# NPCX498S register map
File version: 1.0
Registers are 8-bit, read-write, reset 0x0 unless marked. A register's access mark holds for its fields unless they carry their own. Offsets are from the block's base; [hi:lo] are bit positions; {n}, {i} and the like mark numbered series.

## SYS_CONFIG
Base 0x400C3000
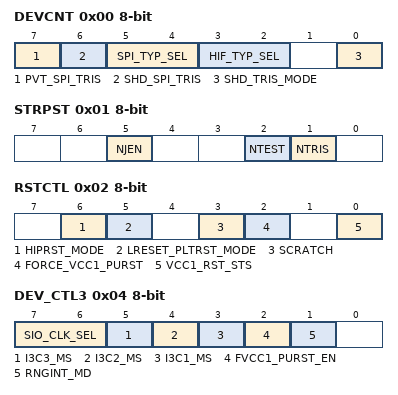
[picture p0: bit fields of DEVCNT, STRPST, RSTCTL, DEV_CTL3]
0x00 DEVCNT — Device Control Register (DEVCNT)
  [7] PVT_SPI_TRIS — Private Flash SPI Interface TRI-STATE
  [6] SHD_SPI_TRIS — Shared Flash SPI Interface TRI-STATE
  [5:4] SPI_TYP_SEL — SPI Interface Type Select
  [3:2] HIF_TYP_SEL — Host Interface Type Select
  [0] SHD_TRIS_MODE — Shared Flash SPI TRI-STATE Mode
0x01 STRPST — Straps Status Register (STRPST)
  [5] NJEN — JTAG Strap
  [2] NTEST — XOR-Tree Test Mode
  [1] NTRIS — TRI-STATE Test Mode
0x02 RSTCTL — Reset Control and Status Register (RSTCTL)
  [6] HIPRST_MODE — Host Interface Modules Reset Mode Select
  [5] LRESET_PLTRST_MODE — LRESET or PLTRST Mode Select
  [3] SCRATCH
  [2] FORCE_VCC1_PURST — Force VCC1 Power-Up Reset
  [0] VCC1_RST_STS — VCC1_RST Status
0x04 DEV_CTL3 — Device Control 3 Register (DEV_CTL3)
  [7:6] SIO_CLK_SEL — SIO Modules Clock Select
  [5] I3C3_MS — I3CI3 Module Controller/Target Select
  [4] I3C2_MS — I3CI2 Module Controller/Target Select
  [3] I3C1_MS — I3CI1 Module Controller/Target Select
  [2] FVCC1_PURST_EN — Force VCC1 Power-Up Reset Enable
  [1] RNGINT_MD — RNG Modules Interrupt Mode
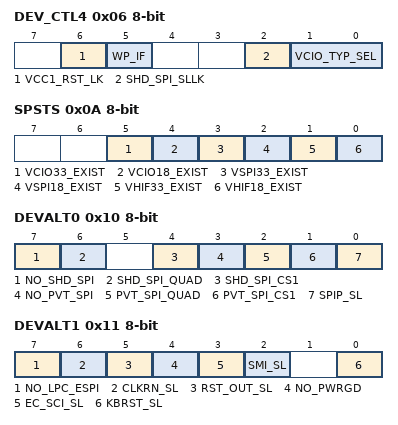
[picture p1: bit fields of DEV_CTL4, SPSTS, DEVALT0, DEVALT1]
0x06 DEV_CTL4 — Device Control 4 Register (DEV_CTL4)
  [6] VCC1_RST_LK — NO_VCC1_RST Bit Lock
  [5] WP_IF — Write-Protect Internal Flash
  [2] SHD_SPI_SLLK — Shared Flash SPI Interface-Select Lock
  [1:0] VCIO_TYP_SEL — VCIO Supply Type Select
0x0A SPSTS — Supply Status Register (SPSTS)
  [5] VCIO33_EXIST — 3.3V VCIO Supply Level
  [4] VCIO18_EXIST — 1.8V VCIO Supply Level
  [3] VSPI33_EXIST — 3.3V SPI Flash Supply Level
  [2] VSPI18_EXIST — 1.8V SPI Flash Supply Level
  [1] VHIF33_EXIST — 3.3V Host Interface Supply Level
  [0] VHIF18_EXIST — 1.8V Host Interface Supply Level
0x10 DEVALT0 — Device Alternate Function 0 Register (DEVALT0)
  [7] NO_SHD_SPI — No Shared SPI Flash-Select
  [6] SHD_SPI_QUAD — Shared SPI Flash Quad Interface-Select
  [4] SHD_SPI_CS1 — Shared SPI Flash Chip-Select 1
  [3] NO_PVT_SPI — No Private SPI Flash-Select
  [2] PVT_SPI_QUAD — Private SPI Flash Quad Interface-Select
  [1] PVT_SPI_CS1 — Private SPI Flash Chip-Select 1 Select
  [0] SPIP_SL — SPI Peripheral Interface-Select
0x11 DEVALT1 — Device Alternate Function 1 Register (DEVALT1)
  [7] NO_LPC_ESPI — No LPC or eSPI Interface-Select
  [6] CLKRN_SL — CLKRUN Select
  [5] RST_OUT_SL — RESET_OUT Select
  [4] NO_PWRGD — No PWRGD Select
  [3] EC_SCI_SL — EC_SCI Select
  [2] SMI_SL — SMI Select
  [0] KBRST_SL — KBRST Select
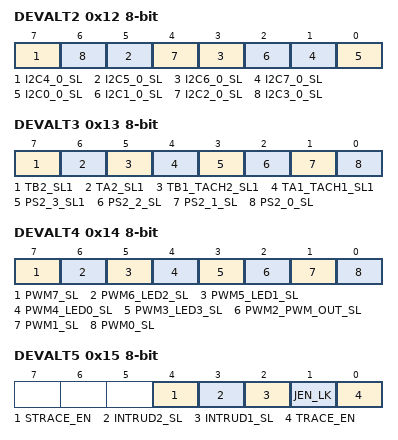
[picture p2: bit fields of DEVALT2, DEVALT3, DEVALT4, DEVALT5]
0x12 DEVALT2 — Device Alternate Function 2 Register (DEVALT2)
  [15-2n] I2C{n}_0_SL (n=4..7) — SMBus/I2C Module {n}, Bus 0 Select
  [2n] I2C{n}_0_SL (n=0..3) — SMBus/I2C Module {n}, Bus 0 Select
0x13 DEVALT3 — Device Alternate Function 3 Register (DEVALT3)
  [7] TB2_SL1 — TB2 Select-1
  [6] TA2_SL1 — TA2 Select-1
  [5] TB1_TACH2_SL1 — TB1_TACH2PWM_IN Select-1
  [4] TA1_TACH1_SL1 — TA1_TACH1 Select-1
  [3] PS2_3_SL1 — PS/2 #3 Select-1
  [2] PS2_2_SL — PS/2 #2 Select
  [1] PS2_1_SL — PS/2 #1 Select
  [0] PS2_0_SL — PS/2 #0 Select
0x14 DEVALT4 — Device Alternate Function 4 Register (DEVALT4)
  [7] PWM7_SL — PWM7 Select
  [6] PWM6_LED2_SL — PWM6_LED2 Select
  [5] PWM5_LED1_SL — PWM5_LED1 Select
  [4] PWM4_LED0_SL — PWM4_LED0 Select
  [3] PWM3_LED3_SL — PWM3_LED3 Select
  [2] PWM2_PWM_OUT_SL — PWM2_TACH2PWM_OUT Select
  [1] PWM1_SL — PWM1 Select
  [0] PWM0_SL — PWM0 Select
0x15 DEVALT5 — Device Alternate Function 5 Register (DEVALT5)
  [4] STRACE_EN — Serial Trace Enable
  [3] INTRUD2_SL — Intruder Detect 2 Select
  [2] INTRUD1_SL — Intruder Detect 1 Select
  [1] JEN_LK — JTAG Enable Lock
  [0] TRACE_EN — Parallel Trace Signals Enable
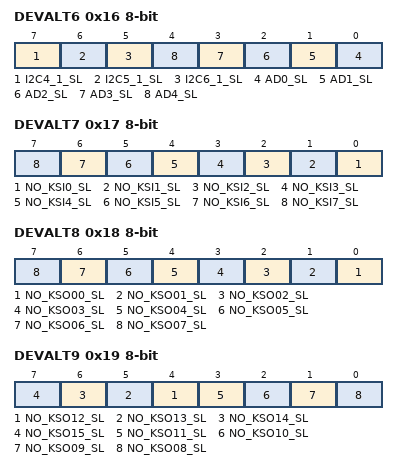
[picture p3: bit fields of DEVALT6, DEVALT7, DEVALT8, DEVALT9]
0x16 DEVALT6 — Device Alternate Function 6 Register (DEVALT6)
  [7] I2C4_1_SL — SMBus/I2C Module 4, Bus 1 Select
  [6] I2C5_1_SL — SMBus/I2C Module 5, Bus 1 Select
  [5] I2C6_1_SL — SMBus/I2C Module 6, Bus 1 Select
  [n] AD{n}_SL (n=0..4) — AD{n} Select
0x17 DEVALT7 — Device Alternate Function 7 Register (DEVALT7)
  [n] NO_KSI{n}_SL (n=0..7) — No KSI{n} Select
0x18 DEVALT8 — Device Alternate Function 8 Register (DEVALT8)
  [n] NO_KSO{n:02}_SL (n=0..7) — No KSO{n:02} Select
0x19 DEVALT9 — Device Alternate Function 9 Register (DEVALT9)
  [n-8] NO_KSO{n}_SL (n=12..15) — No KSO{n} Select
  [3] NO_KSO11_SL — No KSO11 and P80_DAT Select
  [2] NO_KSO10_SL — No KSO10 and P80_CLK Select
  [1] NO_KSO09_SL — No KSO09 Select
  [0] NO_KSO08_SL — No KSO08 Select
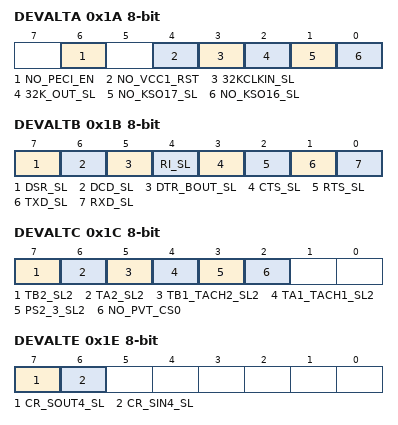
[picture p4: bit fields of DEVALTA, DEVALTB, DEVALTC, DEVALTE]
0x1A DEVALTA — Device Alternate Function A Register (DEVALTA)
  [6] NO_PECI_EN — No PECI Enable
  [4] NO_VCC1_RST — No VCC1_RST Select
  [3] 32KCLKIN_SL — 32KCLKIN Select
  [2] 32K_OUT_SL — 32KHZ_OUT Select
  [1] NO_KSO17_SL — No KSO17 Select
  [0] NO_KSO16_SL — No KSO16 Select
0x1B DEVALTB — Device Alternate Function B Register (DEVALTB)
  [7] DSR_SL — DSR Select
  [6] DCD_SL — DCD Select
  [5] DTR_BOUT_SL — DTR_BOUT Select
  [4] RI_SL — RI Select
  [3] CTS_SL — CTS Select
  [2] RTS_SL — RTS Select
  [1] TXD_SL — TXD Select
  [0] RXD_SL — RXD Select
0x1C DEVALTC — Device Alternate Function C Register (DEVALTC)
  [7] TB2_SL2 — TB2 Select-2
  [6] TA2_SL2 — TA2 Select-2
  [5] TB1_TACH2_SL2 — TB1_TACH2PWM_IN Select-2
  [4] TA1_TACH1_SL2 — TA1_TACH1 Select-2
  [3] PS2_3_SL2 — PS/2 #3 Select-2
  [2] NO_PVT_CS0 — No Private SPI Flash Chip-Select 0 Select
0x1E DEVALTE — Device Alternate Function E Register (DEVALTE)
  [7] CR_SOUT4_SL — CR_SOUT4 Select
  [6] CR_SIN4_SL — CR_SIN4 Select
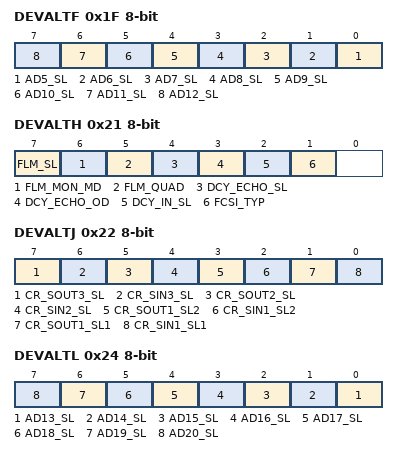
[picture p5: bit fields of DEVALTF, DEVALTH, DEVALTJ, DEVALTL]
0x1F DEVALTF — Device Alternate Function F Register (DEVALTF)
  [n-5] AD{n}_SL (n=5..12) — AD{n} Select
0x21 DEVALTH — Device Alternate Function H Register (DEVALTH)
  [7] FLM_SL — FLM Interface-Select
  [6] FLM_MON_MD — FLM in Monitoring Mode
  [5] FLM_QUAD — FLM Quad Interface-Select
  [4] DCY_ECHO_SL — DCY_ECHO Select
  [3] DCY_ECHO_OD — DCY_ECHO Open-Drain Select
  [2] DCY_IN_SL — DCY_IN Select
  [1] FCSI_TYP — FLM_CSI Type
0x22 DEVALTJ — Device Alternate Function J Register (DEVALTJ)
  [7] CR_SOUT3_SL — CR_SOUT3 Select
  [6] CR_SIN3_SL — CR_SIN3 Select
  [5] CR_SOUT2_SL — CR_SOUT2 Select
  [4] CR_SIN2_SL — CR_SIN2 Select
  [3] CR_SOUT1_SL2 — CR_SOUT1 Select-2
  [2] CR_SIN1_SL2 — CR_SIN1 Select-2
  [1] CR_SOUT1_SL1 — CR_SOUT1 Select-1
  [0] CR_SIN1_SL1 — CR_SIN1 Select-1
0x23 DEVALTK — Device Alternate Function K Register (DEVALTK)
  [7] I2C7_1_SL — SMBus/I2C Module 7, Bus 1 Select
0x24 DEVALTL — Device Alternate Function L Register (DEVALTL)
  [n-13] AD{n}_SL (n=13..20) — AD{n} Select
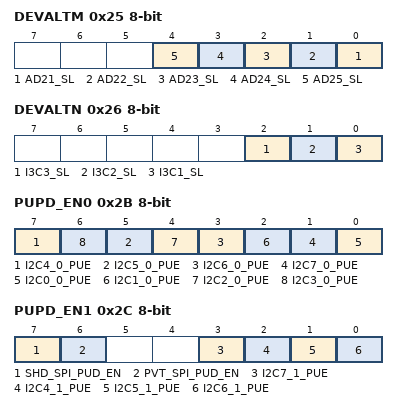
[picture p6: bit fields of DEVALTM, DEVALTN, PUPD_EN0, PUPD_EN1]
0x25 DEVALTM — Device Alternate Function M Register (DEVALTM)
  [n-21] AD{n}_SL (n=21..25) — AD{n} Select
0x26 DEVALTN — Device Alternate Function N Register (DEVALTN)
  [2] I3C3_SL — I3C3 Signals Select
  [1] I3C2_SL — I3C2 Signals Select
  [0] I3C1_SL — I3C1 Signals Select
0x2B PUPD_EN0 — Pull-Up/Pull-Down Enable 0 Register (PUPD_EN0)
  [15-2n] I2C{n}_0_PUE (n=4..7) — SMBus/I2C Module {n}, Bus 0 Pull-Up Enable
  [2n] I2C{n}_0_PUE (n=0..3) — SMBus/I2C Module {n}, Bus 0 Pull-Up Enable
0x2C PUPD_EN1 — Pull-Up/Pull-Down Enable 1 Register (PUPD_EN1)
  [7] SHD_SPI_PUD_EN — Shared SPI Flash Pull-Up/Down Enable
  [6] PVT_SPI_PUD_EN — Private SPI Flash Pull-Up/Down Enable
  [3] I2C7_1_PUE — SMBus/I2C Module 7, Bus 1 Pull-Up Enable
  [2] I2C4_1_PUE — SMBus/I2C Module 4, Bus 1 Pull-Up Enable
  [1] I2C5_1_PUE — SMBus/I2C Module 5, Bus 1 Pull-Up Enable
  [0] I2C6_1_PUE — SMBus/I2C Module 6, Bus 1 Pull-Up Enable
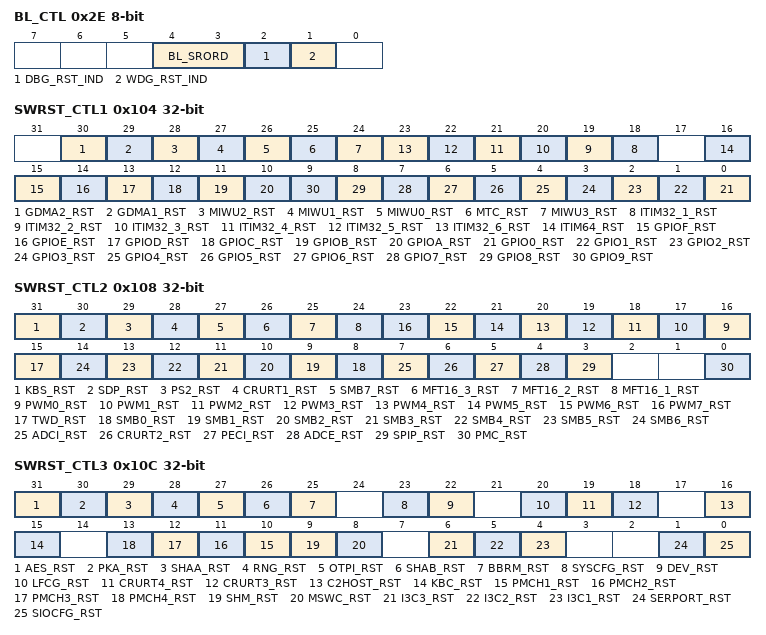
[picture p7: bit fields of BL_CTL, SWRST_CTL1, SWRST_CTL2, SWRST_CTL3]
0x2E BL_CTL — BootLoader Control Register (BL_CTL)
  [4:3] BL_SRORD — BootLoader Search Order
  [2] DBG_RST_IND — Debugger Reset Indication
  [1] WDG_RST_IND — Watchdog Reset Indication
0x100 SWRST_TRG 16-bit (reset mask 0xFF) — Software Reset Trigger Register (SWRST_TRG)
0x104 SWRST_CTL1 32-bit (reset mask 0xFF) — Software Reset Control 1 Register (SWRST_CTL1)
  [30] GDMA2_RST — GDMA2 Reset
  [29] GDMA1_RST — GDMA1 Reset
  [28] MIWU2_RST — MIWU2 Reset
  [27] MIWU1_RST — MIWU1 Reset
  [26] MIWU0_RST — MIWU0 Reset
  [25] MTC_RST — MTC Reset
  [24] MIWU3_RST — MIWU2 Reset
  [n+17] ITIM32_{n}_RST (n=1..6) — ITIM32-{n} Reset
  [16] ITIM64_RST — ITIM64 Reset
  [15] GPIOF_RST — GPIO Port F Reset
  [14] GPIOE_RST — GPIO Port E Reset
  [13] GPIOD_RST — GPIO Port D Reset
  [12] GPIOC_RST — GPIO Port C Reset
  [11] GPIOB_RST — GPIO Port B Reset
  [10] GPIOA_RST — GPIO Port A Reset
  [n] GPIO{n}_RST (n=0..9) — GPIO Port {n} Reset
0x108 SWRST_CTL2 32-bit (reset mask 0xFF) — Software Reset Control 2 Register (SWRST_CTL2)
  [31] KBS_RST — Keyboard Scan Reset
  [30] SDP_RST — SDP Reset
  [29] PS2_RST — PS/2 Reset
  [28] CRURT1_RST — CR_UART 1 Reset
  [27] SMB7_RST — SMB7 Reset
  [26] MFT16_3_RST — MFT16-3 Reset
  [25] MFT16_2_RST — MFT16-2 Reset
  [24] MFT16_1_RST — MFT16-1 Reset
  [n+16] PWM{n}_RST (n=0..7) — PWM{n} Reset
  [15] TWD_RST — TWD Reset
  [n+8] SMB{n}_RST (n=0..6) — SMB{n} Reset
  [7] ADCI_RST — ADC_IREF Reset
  [6] CRURT2_RST — CR_UART 2 Reset
  [5] PECI_RST — PECI Reset
  [4] ADCE_RST — ADC_EREF Reset
  [3] SPIP_RST — SPI Peripheral Reset
  [0] PMC_RST — PMC Reset
0x10C SWRST_CTL3 32-bit (reset mask 0xFF) — Software Reset Control 3 Register (SWRST_CTL3)
  [31] AES_RST — AES Reset
  [30] PKA_RST — PKA Reset
  [29] SHAA_RST — SHAa Reset
  [28] RNG_RST — RNG Reset
  [27] OTPI_RST — OTPI Reset
  [26] SHAB_RST — SHAb Reset
  [25] BBRM_RST — BBRM Reset
  [23] SYSCFG_RST — SYSCFG Reset
  [22] DEV_RST — Development Reset
  [20] LFCG_RST — LFCG Reset
  [19] CRURT4_RST — CR_UART 4 Reset
  [18] CRURT3_RST — CR_UART 3 Reset
  [16] C2HOST_RST — Core-to-Host Reset
  [15] KBC_RST — KBC Reset
  [n+9] PMCH{n}_RST (n=1..4) — PM Channel {n} Reset
  [9] SHM_RST — SHM Reset
  [8] MSWC_RST — MSWC Reset
  [6] I3C3_RST — I3CI3 Reset
  [5] I3C2_RST — I3CI2 Reset
  [4] I3C1_RST — I3CI1 Reset
  [1] SERPORT_RST — Serial Port Reset
  [0] SIOCFG_RST — SuperI/O Configuration Reset
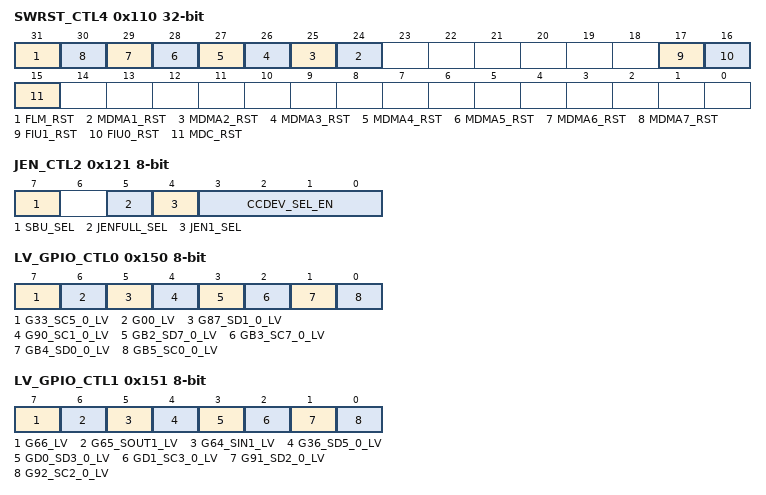
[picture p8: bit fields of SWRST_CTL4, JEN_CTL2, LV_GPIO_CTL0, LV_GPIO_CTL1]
0x110 SWRST_CTL4 32-bit (reset mask 0xFF) — Software Reset Control 4 Register (SWRST_CTL4)
  [31] FLM_RST — FLM Reset
  [n+23] MDMA{n}_RST (n=1..7) — MDMA{n} Reset
  [17] FIU1_RST — FIU1 Reset
  [16] FIU0_RST — FIU0 Reset
  [15] MDC_RST — MDC Reset
0x120 JEN_CTL1 — JTAG Enable Control 1 Register (JEN_CTL1)
  [3:0] JEN_EN — JTAG Enable
0x121 JEN_CTL2 — JTAG Enable Control 2 Register (JEN_CTL2)
  [7] SBU_SEL — SBU Signals Connection Select
  [5] JENFULL_SEL — JTAG Full Set Select
  [4] JEN1_SEL — JTAG 1 Select
  [3:0] CCDEV_SEL_EN — CCDEV Select Enable
0x150 LV_GPIO_CTL0 — Low-Voltage GPIO Pins Control 0 Register (LV_GPIO_CTL0)
  [7] G33_SC5_0_LV — GPIO33/I2C5_SCL0 Low-Voltage Select
  [6] G00_LV — GPIO00 Low-Voltage Select
  [5] G87_SD1_0_LV — GPIO87/I2C1_SDA0 Low-Voltage Select
  [4] G90_SC1_0_LV — GPIO90/I2C1_SCL0 Low-Voltage Select
  [3] GB2_SD7_0_LV — GPIOB2/I2C7_SDA0 Low-Voltage Select
  [2] GB3_SC7_0_LV — GPIOB3/I2C7_SCL0 Low-Voltage Select
  [1] GB4_SD0_0_LV — GPIOB4/I2C0_SDA0 Low-Voltage Select
  [0] GB5_SC0_0_LV — GPIOB5/I2C0_SCL0 Low-Voltage Select
0x151 LV_GPIO_CTL1 — Low-Voltage GPIO Pins Control 1 Register (LV_GPIO_CTL1)
  [7] G66_LV — GPIO66 Low-Voltage Select
  [6] G65_SOUT1_LV — GPIO65/CR_SOUT1 Low-Voltage Select
  [5] G64_SIN1_LV — GPIO64/CR_SIN1 Low-Voltage Select
  [4] G36_SD5_0_LV — GPIO36/I2C5_SDA0 Low-Voltage Select
  [3] GD0_SD3_0_LV — GPIOD0/I2C3_SDA0 Low-Voltage Select
  [2] GD1_SC3_0_LV — GPIOD1/I2C3_SCL0 Low-Voltage Select
  [1] G91_SD2_0_LV — GPIO91/I2C2_SDA0 Low-Voltage Select
  [0] G92_SC2_0_LV — GPIO92/I2C2_SCL0 Low-Voltage Select
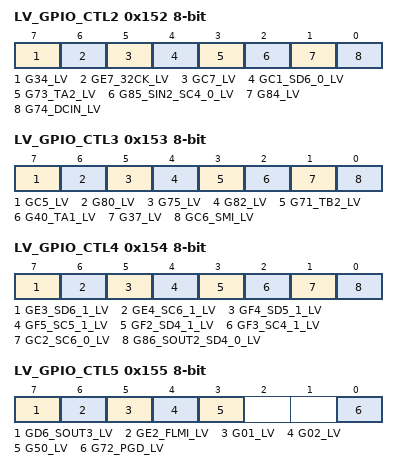
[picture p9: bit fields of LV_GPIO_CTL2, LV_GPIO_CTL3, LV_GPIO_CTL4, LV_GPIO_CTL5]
0x152 LV_GPIO_CTL2 — Low-Voltage GPIO Pins Control 2 Register (LV_GPIO_CTL2)
  [7] G34_LV — GPIO34 Low-Voltage Select
  [6] GE7_32CK_LV — GPIOE7/32KCLKIN Low-Voltage Select
  [5] GC7_LV — GPIOC7 Low-Voltage Select
  [4] GC1_SD6_0_LV — GPIOC1/I2C6_SDA0 Low-Voltage Select
  [3] G73_TA2_LV — GPIO73/TA2 Low-Voltage Select
  [2] G85_SIN2_SC4_0_LV — GPIO85/CR_SIN2/I2C4_SCL0 Low-Voltage Select
  [1] G84_LV — GPIO84 Low-Voltage Select
  [0] G74_DCIN_LV — GPIO74/DCY_IN Low-Voltage Select
0x153 LV_GPIO_CTL3 — Low-Voltage GPIO Pins Control 3 Register (LV_GPIO_CTL3)
  [7] GC5_LV — GPIOC5 Low-Voltage Select
  [6] G80_LV — GPIO80 Low-Voltage Select
  [5] G75_LV — GPIO75 Low-Voltage Select
  [4] G82_LV — GPIO82 Low-Voltage Select
  [3] G71_TB2_LV — GPIO71/TB2 Low-Voltage Select
  [2] G40_TA1_LV — GPIO40/TA1_TACH1 Low-Voltage Select
  [1] G37_LV — GPIO37 Low-Voltage Select
  [0] GC6_SMI_LV — GPIOC6/SMI Low-Voltage Select
0x154 LV_GPIO_CTL4 — Low-Voltage GPIO Pins Control 4 Register (LV_GPIO_CTL4)
  [7] GE3_SD6_1_LV — GPIOE3/I2C6_SDA1 Low-Voltage Select
  [6] GE4_SC6_1_LV — GPIOE4/I2C6_SCL1 Low-Voltage Select
  [5] GF4_SD5_1_LV — GPIOF4/I2C5_SDA1 Low-Voltage Select
  [4] GF5_SC5_1_LV — GPIOF5/I2C5_SCL1 Low-Voltage Select
  [3] GF2_SD4_1_LV — GPIOF2/I2C4_SDA1 Low-Voltage Select
  [2] GF3_SC4_1_LV — GPIOF3/I2C4_SCL1 Low-Voltage Select
  [1] GC2_SC6_0_LV — GPIOC2/I2C6_SCL0 Low-Voltage Select
  [0] G86_SOUT2_SD4_0_LV — GPIO86/CR_SOUT2/I2C4_SDA0 Low-Voltage Select
0x155 LV_GPIO_CTL5 — Low-Voltage GPIO Pins Control 5 Register (LV_GPIO_CTL5)
  [7] GD6_SOUT3_LV — GPIOD6/CR_SOUT3 Low-Voltage Select
  [6] GE2_FLMI_LV — GPIOE2/FLM_CSI Low-Voltage Select
  [5] G01_LV — GPIO01 Low-Voltage Select
  [4] G02_LV — GPIO02 Low-Voltage Select
  [3] G50_LV — GPIO50 Low-Voltage Select
  [0] G72_PGD_LV — GPIO72 Low-Voltage Select
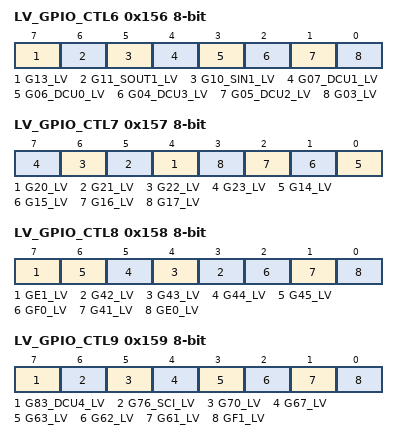
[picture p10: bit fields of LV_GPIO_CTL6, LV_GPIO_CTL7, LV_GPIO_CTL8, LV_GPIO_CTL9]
0x156 LV_GPIO_CTL6 — Low-Voltage GPIO Pins Control 6 Register (LV_GPIO_CTL6)
  [7] G13_LV — GPIO13 Low-Voltage Select
  [6] G11_SOUT1_LV — GPIO11/CR_SOUT1 Low-Voltage Select
  [5] G10_SIN1_LV — GPIO10/CR_SIN1 Low-Voltage Select
  [4] G07_DCU1_LV — GPIO07/DCU1 Low-Voltage Select
  [3] G06_DCU0_LV — GPIO06/DCU0 Low-Voltage Select
  [2] G04_DCU3_LV — GPIO04/DCU3 Low-Voltage Select
  [1] G05_DCU2_LV — GPIO05/DCU2 Low-Voltage Select
  [0] G03_LV — GPIO03 Low-Voltage Select
0x157 LV_GPIO_CTL7 — Low-Voltage GPIO Pins Control 7 Register (LV_GPIO_CTL7)
  [n-16] G{n}_LV (n=20..23) — GPIO{n} Low-Voltage Select
  [n-14] G{n}_LV (n=14..17) — GPIO{n} Low-Voltage Select
0x158 LV_GPIO_CTL8 — Low-Voltage GPIO Pins Control 8 Register (LV_GPIO_CTL8)
  [7] GE1_LV — GPIOE1 Low-Voltage Select
  [n-39] G{n}_LV (n=42..45) — GPIO{n} Low-Voltage Select
  [2] GF0_LV — GPIOF0 Low-Voltage Select
  [1] G41_LV — GPIO41 Low-Voltage Select
  [0] GE0_LV — GPIOE0 Low-Voltage Select
0x159 LV_GPIO_CTL9 — Low-Voltage GPIO Pins Control 9 Register (LV_GPIO_CTL9)
  [7] G83_DCU4_LV — GPIO83/DCU4 Low-Voltage Select
  [6] G76_SCI_LV — GPIO76/EC_SCI Low-Voltage Select
  [5] G70_LV — GPIO70 Low-Voltage Select
  [4] G67_LV — GPIO67 Low-Voltage Select
  [3] G63_LV — GPIO63 Low-Voltage Select
  [2] G62_LV — GPIO62 Low-Voltage Select
  [1] G61_LV — GPIO61 Low-Voltage Select
  [0] GF1_LV — GPIOF1 Low-Voltage Select
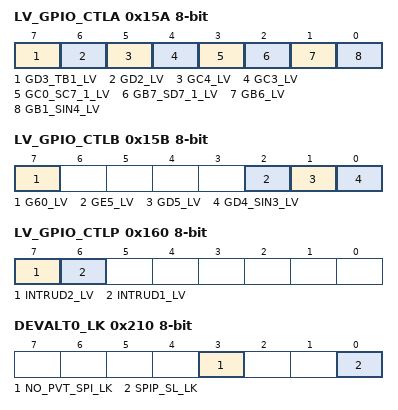
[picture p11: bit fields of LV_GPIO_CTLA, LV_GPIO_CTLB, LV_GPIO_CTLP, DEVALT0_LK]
0x15A LV_GPIO_CTLA — Low-Voltage GPIO Pins Control A Register (LV_GPIO_CTLA)
  [7] GD3_TB1_LV — GPIOD3/TB1_TACH2PWM_IN Low-Voltage Select
  [6] GD2_LV — GPIOD2 Low-Voltage Select
  [5] GC4_LV — GPIOC4 Low-Voltage Select
  [4] GC3_LV — GPIOC3 Low-Voltage Select
  [3] GC0_SC7_1_LV — GPIOC0/I2C7_SCL1 Low-Voltage Select
  [2] GB7_SD7_1_LV — GPIOB7/I2C7_SDA1 Low-Voltage Select
  [1] GB6_LV — GPIOB6 Low-Voltage Select
  [0] GB1_SIN4_LV — GPIOB1/CR_SIN4 Low-Voltage Select
0x15B LV_GPIO_CTLB — Low-Voltage GPIO Pins Control B Register (LV_GPIO_CTLB)
  [7] G60_LV — GPIO60 Low-Voltage Select
  [2] GE5_LV — GPIOE5 Low-Voltage Select
  [1] GD5_LV — GPIOD5 Low-Voltage Select
  [0] GD4_SIN3_LV — GPIOD4/CR_SIN3 Low-Voltage Select
0x160 LV_GPIO_CTLP — Low-Voltage GPIO Pins Control P Register (LV_GPIO_CTLP)
  [7] INTRUD2_LV — INTRUDER2 Low-Voltage Select
  [6] INTRUD1_LV — INTRUDER1 Low-Voltage Select
0x210 DEVALT0_LK — Device Alternate Function 0 Lock Register (DEVALT0_LK)
  [3] NO_PVT_SPI_LK — No Private SPI Flash-Select Lock
  [0] SPIP_SL_LK — SPI Peripheral Interface-Select Lock
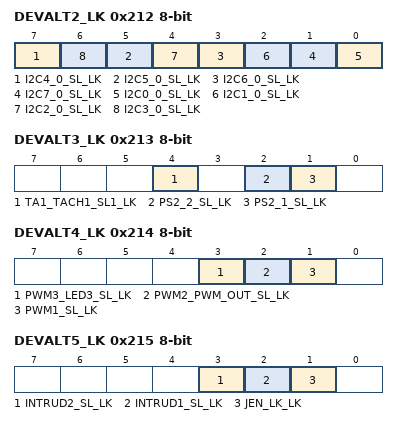
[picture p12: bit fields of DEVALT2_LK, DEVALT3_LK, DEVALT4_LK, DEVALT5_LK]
0x212 DEVALT2_LK — Device Alternate Function 2 Lock Register (DEVALT2_LK)
  [15-2n] I2C{n}_0_SL_LK (n=4..7) — SMBus/I2C Module {n}, Bus 0 Select Lock
  [2n] I2C{n}_0_SL_LK (n=0..3) — SMBus/I2C Module {n}, Bus 0 Select Lock
0x213 DEVALT3_LK — Device Alternate Function 3 Lock Register (DEVALT3_LK)
  [4] TA1_TACH1_SL1_LK — TA1_TACH1 Select-1 Lock
  [2] PS2_2_SL_LK — PS/2 #2 Select Lock
  [1] PS2_1_SL_LK — PS/2 #1 Select Lock
0x214 DEVALT4_LK — Device Alternate Function 4 Lock Register (DEVALT4_LK)
  [3] PWM3_LED3_SL_LK — PWM3_LED3 Select Lock
  [2] PWM2_PWM_OUT_SL_LK — PWM2_TACH2PWM_OUT Select Lock
  [1] PWM1_SL_LK — PWM1 Select Lock
0x215 DEVALT5_LK — Device Alternate Function 5 Lock Register (DEVALT5_LK)
  [3] INTRUD2_SL_LK — Intruder 2 Detect Select Lock
  [2] INTRUD1_SL_LK — Intruder 1 Detect Select Lock
  [1] JEN_LK_LK — JTAG Enable Lock, Lock
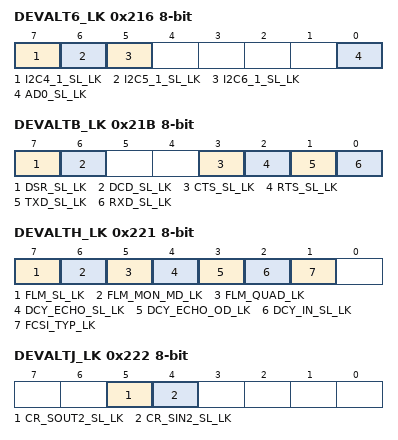
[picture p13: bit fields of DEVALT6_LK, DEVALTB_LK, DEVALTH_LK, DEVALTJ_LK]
0x216 DEVALT6_LK — Device Alternate Function 6 Lock Register (DEVALT6_LK)
  [7] I2C4_1_SL_LK — SMBus/I2C Module 4, Bus 1 Select Lock
  [6] I2C5_1_SL_LK — SMBus/I2C Module 5, Bus 1 Select Lock
  [5] I2C6_1_SL_LK — SMBus/I2C Module 6, Bus 1 Select Lock
  [0] AD0_SL_LK — AD0 Select Lock
0x21B DEVALTB_LK — Device Alternate Function B Lock Register (DEVALTB_LK)
  [7] DSR_SL_LK — DSR Select Lock
  [6] DCD_SL_LK — DCD Select Lock
  [3] CTS_SL_LK — CTS Select Lock
  [2] RTS_SL_LK — RTS Select Lock
  [1] TXD_SL_LK — TXD Select Lock
  [0] RXD_SL_LK — RXD Select Lock
0x21F DEVALTF_LK — Device Alternate Function F Lock Register (DEVALTF_LK)
  [0] AD5_SL_LK — AD5 Select Lock
0x221 DEVALTH_LK — Alternate Function H Lock Register (DEVALTH_LK)
  [7] FLM_SL_LK — FLM Interface-Select Lock
  [6] FLM_MON_MD_LK — FLM in Monitoring Mode Lock
  [5] FLM_QUAD_LK — FLM Quad Interface-Select Lock
  [4] DCY_ECHO_SL_LK — DCY_ECHO Select Lock
  [3] DCY_ECHO_OD_LK — DCY_ECHO Open-Drain Select Lock
  [2] DCY_IN_SL_LK — DCY_IN Select Lock
  [1] FCSI_TYP_LK — FLM_CSI Type Lock
0x222 DEVALTJ_LK — Device Alternate Function J Lock Register (DEVALTJ_LK)
  [5] CR_SOUT2_SL_LK — CR_SOUT2 Select Lock
  [4] CR_SIN2_SL_LK — CR_SIN2 Select Lock
0x223 DEVALTK_LK — Device Alternate Function K Lock Register (DEVALTK_LK)
  [7] I2C7_1_SL_LK — SMBus/I2C Module 7, Bus 1 Select Lock
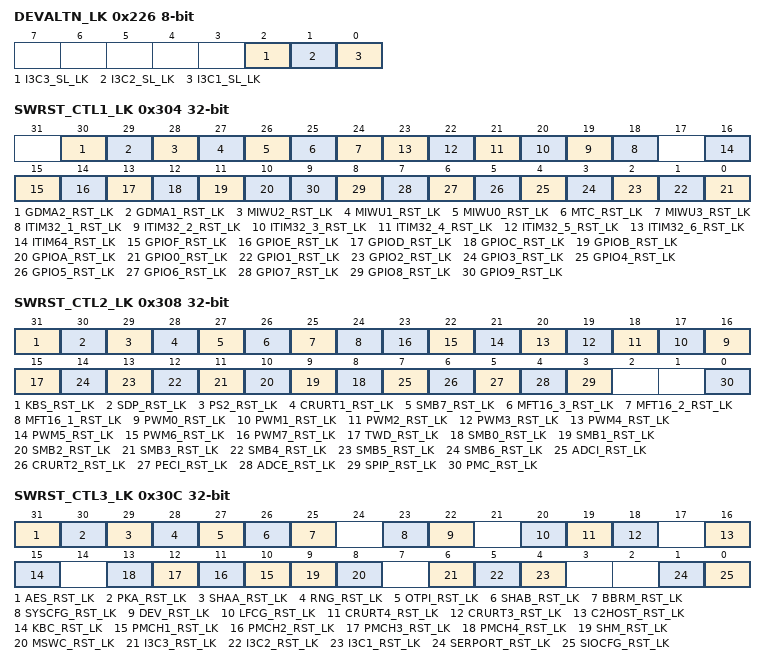
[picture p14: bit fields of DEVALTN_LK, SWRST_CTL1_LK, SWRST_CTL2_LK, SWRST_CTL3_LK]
0x226 DEVALTN_LK — Device Alternate Function N Lock Register (DEVALTN_LK)
  [2] I3C3_SL_LK — I3C3 Signals Select Lock
  [1] I3C2_SL_LK — I3C2 Signals Select Lock
  [0] I3C1_SL_LK — I3C1 Signals Select Lock
0x304 SWRST_CTL1_LK 32-bit (reset mask 0xFF) — Software Reset Control 1 Lock Register (SWRST_CTL1_LK)
  [30] GDMA2_RST_LK — GDMA2 Reset Lock
  [29] GDMA1_RST_LK — GDMA1 Reset Lock
  [28] MIWU2_RST_LK — MIWU2 Reset Lock
  [27] MIWU1_RST_LK — MIWU1 Reset Lock
  [26] MIWU0_RST_LK — MIWU0 Reset Lock
  [25] MTC_RST_LK — MTC Reset Lock
  [24] MIWU3_RST_LK — MIWU3 Reset Lock
  [n+17] ITIM32_{n}_RST_LK (n=1..6) — ITIM32-{n} Reset Lock
  [16] ITIM64_RST_LK — ITIM64 Reset Lock
  [15] GPIOF_RST_LK — GPIO Port F Reset Lock
  [14] GPIOE_RST_LK — GPIO Port E Reset Lock
  [13] GPIOD_RST_LK — GPIO Port D Reset Lock
  [12] GPIOC_RST_LK — GPIO Port C Reset Lock
  [11] GPIOB_RST_LK — GPIO Port B Reset Lock
  [10] GPIOA_RST_LK — GPIO Port A Reset Lock
  [n] GPIO{n}_RST_LK (n=0..9) — GPIO Port {n} Reset Lock
0x308 SWRST_CTL2_LK 32-bit (reset mask 0xFF) — Software Reset Control 2 Lock Register (SWRST_CTL2_LK)
  [31] KBS_RST_LK — Keyboard Scan Reset Lock
  [30] SDP_RST_LK — SDP Reset Lock
  [29] PS2_RST_LK — PS/2 Reset Lock
  [28] CRURT1_RST_LK — CR_UART 1 Reset Lock
  [27] SMB7_RST_LK — SMB7 Reset Lock
  [26] MFT16_3_RST_LK — MFT16-3 Reset Lock
  [25] MFT16_2_RST_LK — MFT16-2 Reset Lock
  [24] MFT16_1_RST_LK — MFT16-1 Reset Lock
  [n+16] PWM{n}_RST_LK (n=0..7) — PWM{n} Reset Lock
  [15] TWD_RST_LK — TWD Reset Lock
  [n+8] SMB{n}_RST_LK (n=0..6) — SMB{n} Reset Lock
  [7] ADCI_RST_LK — ADC_IREF Reset Lock
  [6] CRURT2_RST_LK — CR_UART 2 Reset Lock
  [5] PECI_RST_LK — PECI Reset Lock
  [4] ADCE_RST_LK — ADC_EREF Reset Lock
  [3] SPIP_RST_LK — SPI Peripheral Reset Lock
  [0] PMC_RST_LK — PMC Reset Lock
0x30C SWRST_CTL3_LK 32-bit (reset mask 0xFF) — Software Reset Control 3 Lock Register (SWRST_CTL3_LK)
  [31] AES_RST_LK — AES Reset Lock
  [30] PKA_RST_LK — PKA Reset Lock
  [29] SHAA_RST_LK — SHAa Reset Lock
  [28] RNG_RST_LK — RNG Reset Lock
  [27] OTPI_RST_LK — OTPI Reset Lock
  [26] SHAB_RST_LK — SHAb Reset Lock
  [25] BBRM_RST_LK — BBRM Reset Lock
  [23] SYSCFG_RST_LK — SYSCFG Reset Lock
  [22] DEV_RST_LK — Development Reset Lock
  [20] LFCG_RST_LK — LFCG Reset Lock
  [19] CRURT4_RST_LK — CR_UART 4 Reset Lock
  [18] CRURT3_RST_LK — CR_UART 3 Reset Lock
  [16] C2HOST_RST_LK — Core-to-Host Reset Lock
  [15] KBC_RST_LK — KBC Reset Lock
  [n+9] PMCH{n}_RST_LK (n=1..4) — PM Channel {n} Reset Lock
  [9] SHM_RST_LK — SHM Reset Lock
  [8] MSWC_RST_LK — MSWC Reset Lock
  [6] I3C3_RST_LK — I3C3 Reset Lock
  [5] I3C2_RST_LK — I3C2 Reset Lock
  [4] I3C1_RST_LK — I3C1 Reset Lock
  [1] SERPORT_RST_LK — Serial Port Reset Lock
  [0] SIOCFG_RST_LK — SuperI/O Configuration Reset Lock
0x310 SWRST_CTL4_LK 32-bit (reset mask 0xFF) — Software Reset Control 4 Lock Register (SWRST_CTL4_LK)
  [31] FLM_RST_LK — FLM Reset Lock
  [n+23] MDMA{n}_RST_LK (n=1..7) — MDMA{n} Reset Lock
  [17] FIU1_RST_LK — FIU1 Reset Lock
  [16] FIU0_RST_LK — FIU0 Reset Lock
  [15] MDC_RST_LK — MDC Reset Lock
